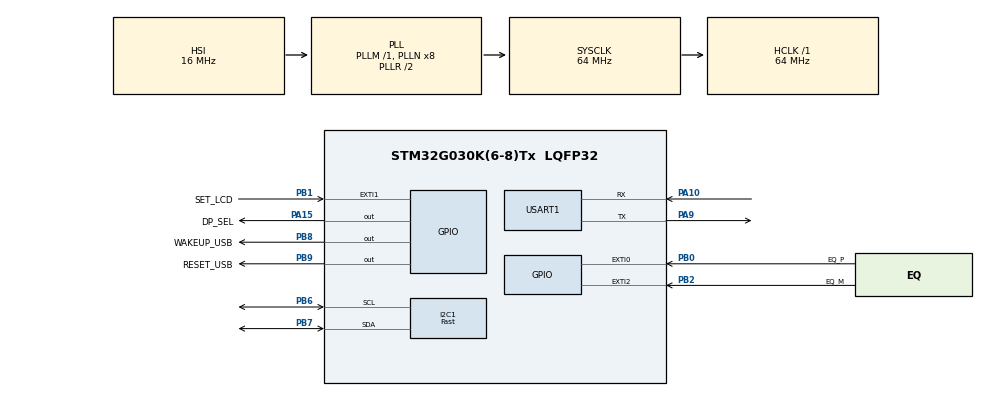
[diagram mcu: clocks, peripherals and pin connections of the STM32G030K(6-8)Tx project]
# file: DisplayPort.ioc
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Dma.Request0=USART1_RX
Dma.USART1_RX.0.Direction=DMA_PERIPH_TO_MEMORY
Dma.USART1_RX.0.EventEnable=DISABLE
Dma.USART1_RX.0.Instance=DMA1_Channel1
Dma.USART1_RX.0.MemDataAlignment=DMA_MDATAALIGN_BYTE
Dma.USART1_RX.0.MemInc=DMA_MINC_ENABLE
Dma.USART1_RX.0.Mode=DMA_NORMAL
Dma.USART1_RX.0.PeriphDataAlignment=DMA_PDATAALIGN_BYTE
Dma.USART1_RX.0.PeriphInc=DMA_PINC_DISABLE
Dma.USART1_RX.0.Polarity=HAL_DMAMUX_REQ_GEN_RISING
Dma.USART1_RX.0.Priority=DMA_PRIORITY_LOW
Dma.USART1_RX.0.RequestNumber=1
Dma.USART1_RX.0.SignalID=NONE
Dma.USART1_RX.0.SyncEnable=DISABLE
Dma.USART1_RX.0.SyncPolarity=HAL_DMAMUX_SYNC_NO_EVENT
Dma.USART1_RX.0.SyncRequestNumber=1
Dma.USART1_RX.0.SyncSignalID=NONE
I2C1.I2C_Speed_Mode=I2C_Fast
I2C1.Timing=0x00602173
Mcu.Family=STM32G0
Mcu.Name=STM32G030K(6-8)Tx
Mcu.Package=LQFP32
NVIC.DMA1_Channel1_IRQn=true\:0\:0\:false\:false\:true\:false\:true\:true
NVIC.EXTI0_1_IRQn=true\:0\:0\:false\:false\:true\:true\:true\:true
NVIC.EXTI2_3_IRQn=true\:0\:0\:false\:false\:true\:true\:true\:true
NVIC.I2C1_IRQn=true\:0\:0\:false\:false\:true\:true\:true\:true
NVIC.USART1_IRQn=true\:0\:0\:false\:false\:true\:true\:true\:true
PA10.Mode=Asynchronous
PA10.Signal=USART1_RX
PA15.GPIO_Label=DP_SEL
PA15.GPIO_Speed=GPIO_SPEED_FREQ_VERY_HIGH
PA15.Signal=GPIO_Output
PA9.Mode=Asynchronous
PA9.Signal=USART1_TX
PB0.GPIO_Label=EQ_P
PB0.GPIO_ModeDefaultEXTI=GPIO_MODE_IT_FALLING
PB0.GPIO_PuPd=GPIO_PULLUP
PB0.Signal=GPXTI0
PB1.GPIO_Label=SET_LCD
PB1.GPIO_ModeDefaultEXTI=GPIO_MODE_IT_FALLING
PB1.GPIO_PuPd=GPIO_PULLUP
PB1.Signal=GPXTI1
PB2.GPIO_Label=EQ_M
PB2.GPIO_ModeDefaultEXTI=GPIO_MODE_IT_FALLING
PB2.GPIO_PuPd=GPIO_PULLUP
PB2.Signal=GPXTI2
PB6.Mode=I2C
PB6.Signal=I2C1_SCL
PB7.Mode=I2C
PB7.Signal=I2C1_SDA
PB8.GPIO_Label=WAKEUP_USB
PB8.GPIO_Speed=GPIO_SPEED_FREQ_VERY_HIGH
PB8.Signal=GPIO_Output
PB9.GPIO_Label=RESET_USB
PB9.GPIO_Speed=GPIO_SPEED_FREQ_VERY_HIGH
PB9.Signal=GPIO_Output
ProjectManager.HeapSize=0x200
ProjectManager.StackSize=0x400
ProjectManager.TargetToolchain=STM32CubeIDE
RCC.ADCFreq_Value=64000000
RCC.AHBFreq_Value=64000000
RCC.CortexFreq_Value=64000000
RCC.EXTERNAL_CLOCK_VALUE=12288000
RCC.HCLKFreq_Value=64000000
RCC.HSE_VALUE=8000000
RCC.HSI_VALUE=16000000
RCC.LSE_VALUE=32768
RCC.SYSCLKFreq_VALUE=64000000
RCC.SYSCLKSource=RCC_SYSCLKSOURCE_PLLCLK
RCC.VCOOutputFreq_Value=128000000
USART1.VirtualMode-Asynchronous=VM_ASYNC
board=custom

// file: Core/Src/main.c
/* USER CODE BEGIN Header */
/**
  ******************************************************************************
  * @file           : main.c
  * @brief          : Main program body
  ******************************************************************************
  * @attention
  *
  * Copyright (c) 2023 STMicroelectronics.
  * All rights reserved.
  *
  * This software is licensed under terms that can be found in the LICENSE file
  * in the root directory of this software component.
  * If no LICENSE file comes with this software, it is provided AS-IS.
  *
  ******************************************************************************
  */
/* USER CODE END Header */
#include "main.h"
#include "dma.h"
#include "i2c.h"
#include "usart.h"
#include "gpio.h"
#include "Drivers/dp_switch.h"
#include "Drivers/equalizer.h"

void SystemClock_Config(void);

int main(void)
{
  /* USER CODE BEGIN 1 */
  dpSwitch_t dp = DP1;

  /* USER CODE END 1 */

  /* MCU Configuration--------------------------------------------------------*/

  /* Reset of all peripherals, Initializes the Flash interface and the Systick. */
  HAL_Init();

  /* Configure the system clock */
  SystemClock_Config();

  /* Initialize all configured peripherals */
  MX_GPIO_Init();
  MX_DMA_Init();
  MX_USART1_UART_Init();
  MX_I2C1_Init();

  buttonsInit();
  eqInit();
  setDp(dp);

  /* Infinite loop */
  /* USER CODE BEGIN WHILE */
  while (1)
  {
    if(buttonsGetState(EQ_GAIN_UP)){
      eqGainSet(EQ_UP);
      buttonsResetState();
    }
    else if(buttonsGetState(EQ_GAIN_DOWN)){
      eqGainSet(EQ_DOWN);
      buttonsResetState();
    }
    else if(buttonsGetState(DP_SWITCH)){
      if(dp == DP1) {
        dp = DP2;
      }
      else {
        dp = DP1;
      }
      setDp(dp);
      buttonsResetState();
    }
  }
  /* USER CODE END 3 */
}

void SystemClock_Config(void)
{
  RCC_OscInitTypeDef RCC_OscInitStruct = {0};
  RCC_ClkInitTypeDef RCC_ClkInitStruct = {0};

  /** Configure the main internal regulator output voltage
  */
  HAL_PWREx_ControlVoltageScaling(PWR_REGULATOR_VOLTAGE_SCALE1);

  /** Initializes the RCC Oscillators according to the specified parameters
  * in the RCC_OscInitTypeDef structure.
  */
  RCC_OscInitStruct.OscillatorType = RCC_OSCILLATORTYPE_HSI;
  RCC_OscInitStruct.HSIState = RCC_HSI_ON;
  RCC_OscInitStruct.HSIDiv = RCC_HSI_DIV1;
  RCC_OscInitStruct.HSICalibrationValue = RCC_HSICALIBRATION_DEFAULT;
  RCC_OscInitStruct.PLL.PLLState = RCC_PLL_ON;
  RCC_OscInitStruct.PLL.PLLSource = RCC_PLLSOURCE_HSI;
  RCC_OscInitStruct.PLL.PLLM = RCC_PLLM_DIV1;
  RCC_OscInitStruct.PLL.PLLN = 8;
  RCC_OscInitStruct.PLL.PLLP = RCC_PLLP_DIV2;
  RCC_OscInitStruct.PLL.PLLR = RCC_PLLR_DIV2;
  if (HAL_RCC_OscConfig(&RCC_OscInitStruct) != HAL_OK)
  {
    Error_Handler();
  }

  /** Initializes the CPU, AHB and APB buses clocks
  */
  RCC_ClkInitStruct.ClockType = RCC_CLOCKTYPE_HCLK|RCC_CLOCKTYPE_SYSCLK
                              |RCC_CLOCKTYPE_PCLK1;
  RCC_ClkInitStruct.SYSCLKSource = RCC_SYSCLKSOURCE_PLLCLK;
  RCC_ClkInitStruct.AHBCLKDivider = RCC_SYSCLK_DIV1;
  RCC_ClkInitStruct.APB1CLKDivider = RCC_HCLK_DIV1;

  if (HAL_RCC_ClockConfig(&RCC_ClkInitStruct, FLASH_LATENCY_2) != HAL_OK)
  {
    Error_Handler();
  }
}

void Error_Handler(void)
{
  __disable_irq();
  while (1)
  {
  }
}
